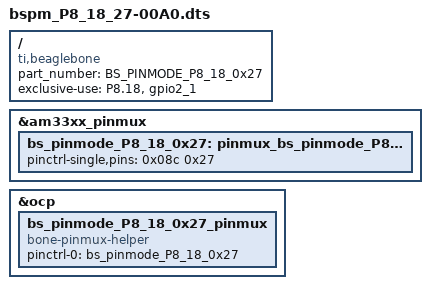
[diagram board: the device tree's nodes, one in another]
/*
 * This is a template-generated file from BoneScript
 */

/*
    # Run on BBB to compile overlay
    dtc -O dtb -o /lib/firmware/bspm_P8_18_27-00A0.dtbo -b 0 -@ /lib/firmware/bspm_P8_18_27-00A0.dts

    # Put this into your /etc/rc.local
    echo bspm_P8_18_27 > /sys/devices/bone_capemgr.?/slots
    echo 65 > /sys/class/gpio/export
*/

/dts-v1/;
/plugin/;

/{
    compatible = "ti,beaglebone", "ti,beaglebone-black";
    part_number = "BS_PINMODE_P8_18_0x27";

    exclusive-use =
        "P8.18",
        "gpio2_1";

    fragment@0 {
        target = <&am33xx_pinmux>;
        __overlay__ {
            bs_pinmode_P8_18_0x27: pinmux_bs_pinmode_P8_18_0x27 {
                pinctrl-single,pins = <0x08c 0x27>;
            };
        };
    };

    fragment@1 {
        target = <&ocp>;
        __overlay__ {
            bs_pinmode_P8_18_0x27_pinmux {
                compatible = "bone-pinmux-helper";
                status = "okay";
                pinctrl-names = "default";
                pinctrl-0 = <&bs_pinmode_P8_18_0x27>;
            };
        };
    };
};
